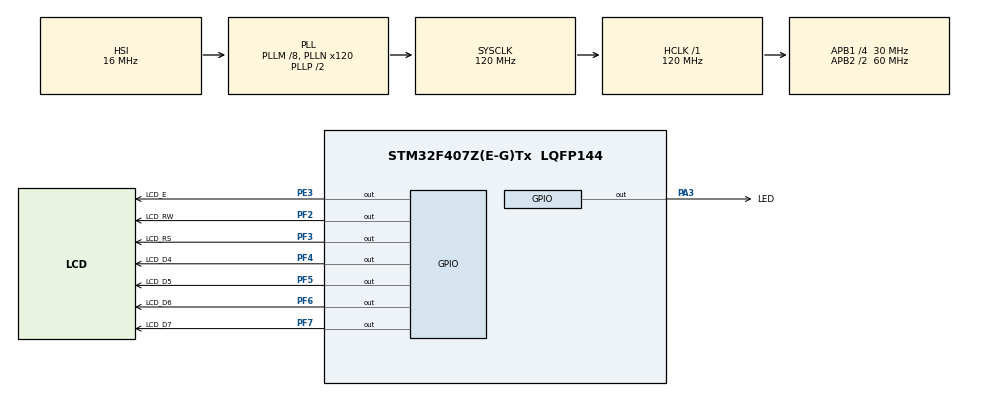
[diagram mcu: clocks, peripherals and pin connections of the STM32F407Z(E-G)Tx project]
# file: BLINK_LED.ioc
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Mcu.Family=STM32F4
Mcu.Name=STM32F407Z(E-G)Tx
Mcu.Package=LQFP144
NVIC.PriorityGroup=NVIC_PRIORITYGROUP_4
PA13.Mode=Serial_Wire
PA13.Signal=SYS_JTMS-SWDIO
PA14.Mode=Serial_Wire
PA14.Signal=SYS_JTCK-SWCLK
PA3.GPIO_Label=LED
PA3.Signal=GPIO_Output
PC14-OSC32_IN.Mode=LSE-External-Oscillator
PC14-OSC32_IN.Signal=RCC_OSC32_IN
PC15-OSC32_OUT.Mode=LSE-External-Oscillator
PC15-OSC32_OUT.Signal=RCC_OSC32_OUT
PE3.GPIO_Label=LCD_E
PE3.Signal=GPIO_Output
PF2.GPIO_Label=LCD_RW
PF2.Signal=GPIO_Output
PF3.GPIO_Label=LCD_RS
PF3.Signal=GPIO_Output
PF4.GPIO_Label=LCD_D4
PF4.Signal=GPIO_Output
PF5.GPIO_Label=LCD_D5
PF5.Signal=GPIO_Output
PF6.GPIO_Label=LCD_D6
PF6.Signal=GPIO_Output
PF7.GPIO_Label=LCD_D7
PF7.Signal=GPIO_Output
PH0-OSC_IN.Mode=HSE-External-Oscillator
PH0-OSC_IN.Signal=RCC_OSC_IN
PH1-OSC_OUT.Mode=HSE-External-Oscillator
PH1-OSC_OUT.Signal=RCC_OSC_OUT
ProjectManager.HeapSize=0x2000
ProjectManager.StackSize=0x4000
ProjectManager.TargetToolchain=MDK-ARM V5
RCC.48MHZClocksFreq_Value=60000000
RCC.AHBFreq_Value=120000000
RCC.APB1CLKDivider=RCC_HCLK_DIV4
RCC.APB1Freq_Value=30000000
RCC.APB1TimFreq_Value=60000000
RCC.APB2CLKDivider=RCC_HCLK_DIV2
RCC.APB2Freq_Value=60000000
RCC.APB2TimFreq_Value=120000000
RCC.CortexFreq_Value=120000000
RCC.HCLKFreq_Value=120000000
RCC.HSE_VALUE=25000000
RCC.HSI_VALUE=16000000
RCC.PLLM=8
RCC.PLLN=120
RCC.SYSCLKFreq_VALUE=120000000
RCC.SYSCLKSource=RCC_SYSCLKSOURCE_PLLCLK
RCC.VCOOutputFreq_Value=240000000
board=custom

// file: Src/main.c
/**
  ******************************************************************************
  * @file           : main.c
  * @brief          : Main program body
  ******************************************************************************
  ** This notice applies to any and all portions of this file
  * that are not between comment pairs USER CODE BEGIN and
  * USER CODE END. Other portions of this file, whether
  * inserted by the user or by software development tools
  * are owned by their respective copyright owners.
  *
  * COPYRIGHT(c) 2023 STMicroelectronics
  *
  * Redistribution and use in source and binary forms, with or without modification,
  * are permitted provided that the following conditions are met:
  *   1. Redistributions of source code must retain the above copyright notice,
  *      this list of conditions and the following disclaimer.
  *   2. Redistributions in binary form must reproduce the above copyright notice,
  *      this list of conditions and the following disclaimer in the documentation
  *      and/or other materials provided with the distribution.
  *   3. Neither the name of STMicroelectronics nor the names of its contributors
  *      may be used to endorse or promote products derived from this software
  *      without specific prior written permission.
  *
  * THIS SOFTWARE IS PROVIDED BY THE COPYRIGHT HOLDERS AND CONTRIBUTORS "AS IS"
  * AND ANY EXPRESS OR IMPLIED WARRANTIES, INCLUDING, BUT NOT LIMITED TO, THE
  * IMPLIED WARRANTIES OF MERCHANTABILITY AND FITNESS FOR A PARTICULAR PURPOSE ARE
  * DISCLAIMED. IN NO EVENT SHALL THE COPYRIGHT HOLDER OR CONTRIBUTORS BE LIABLE
  * FOR ANY DIRECT, INDIRECT, INCIDENTAL, SPECIAL, EXEMPLARY, OR CONSEQUENTIAL
  * DAMAGES (INCLUDING, BUT NOT LIMITED TO, PROCUREMENT OF SUBSTITUTE GOODS OR
  * SERVICES; LOSS OF USE, DATA, OR PROFITS; OR BUSINESS INTERRUPTION) HOWEVER
  * CAUSED AND ON ANY THEORY OF LIABILITY, WHETHER IN CONTRACT, STRICT LIABILITY,
  * OR TORT (INCLUDING NEGLIGENCE OR OTHERWISE) ARISING IN ANY WAY OUT OF THE USE
  * OF THIS SOFTWARE, EVEN IF ADVISED OF THE POSSIBILITY OF SUCH DAMAGE.
  *
  ******************************************************************************
  */
#include "main.h"
#include "stm32f4xx_hal.h"

/* USER CODE BEGIN Includes */
#include "eas_lcd.h"
/* USER CODE END Includes */

/* USER CODE BEGIN PV */
/* Private variables ---------------------------------------------------------*/
uint8_t ucScreen=0;
/* USER CODE END PV */

void SystemClock_Config(void);
static void MX_GPIO_Init(void);

/* USER CODE BEGIN PFP */
/* Private function prototypes -----------------------------------------------*/

/* USER CODE END PFP */

int main(void)
{

  /* MCU Configuration----------------------------------------------------------*/

  /* Reset of all peripherals, Initializes the Flash interface and the Systick. */
  HAL_Init();

  /* Configure the system clock */
  SystemClock_Config();

  /* Initialize all configured peripherals */
  MX_GPIO_Init();
  /* USER CODE BEGIN 2 */
	vLCD_Init();
  /* USER CODE END 2 */

  /* Infinite loop */
  while (1)
  {

  /* USER CODE BEGIN 3 */

		// Show Screen
		if(ucScreen++>=3) ucScreen=0;
		vLCD_Screen(ucScreen);

		// Led Toggle
		HAL_GPIO_TogglePin(LED_GPIO_Port, LED_Pin);
		HAL_Delay(1000);

  }
  /* USER CODE END 3 */

}

void SystemClock_Config(void)
{

  RCC_OscInitTypeDef RCC_OscInitStruct;
  RCC_ClkInitTypeDef RCC_ClkInitStruct;

    /**Configure the main internal regulator output voltage
    */
  __HAL_RCC_PWR_CLK_ENABLE();

  __HAL_PWR_VOLTAGESCALING_CONFIG(PWR_REGULATOR_VOLTAGE_SCALE1);

    /**Initializes the CPU, AHB and APB busses clocks
    */
  RCC_OscInitStruct.OscillatorType = RCC_OSCILLATORTYPE_HSI;
  RCC_OscInitStruct.HSIState = RCC_HSI_ON;
  RCC_OscInitStruct.HSICalibrationValue = 16;
  RCC_OscInitStruct.PLL.PLLState = RCC_PLL_ON;
  RCC_OscInitStruct.PLL.PLLSource = RCC_PLLSOURCE_HSI;
  RCC_OscInitStruct.PLL.PLLM = 8;
  RCC_OscInitStruct.PLL.PLLN = 120;
  RCC_OscInitStruct.PLL.PLLP = RCC_PLLP_DIV2;
  RCC_OscInitStruct.PLL.PLLQ = 4;
  if (HAL_RCC_OscConfig(&RCC_OscInitStruct) != HAL_OK)
  {
    _Error_Handler(__FILE__, __LINE__);
  }

    /**Initializes the CPU, AHB and APB busses clocks
    */
  RCC_ClkInitStruct.ClockType = RCC_CLOCKTYPE_HCLK|RCC_CLOCKTYPE_SYSCLK
                              |RCC_CLOCKTYPE_PCLK1|RCC_CLOCKTYPE_PCLK2;
  RCC_ClkInitStruct.SYSCLKSource = RCC_SYSCLKSOURCE_PLLCLK;
  RCC_ClkInitStruct.AHBCLKDivider = RCC_SYSCLK_DIV1;
  RCC_ClkInitStruct.APB1CLKDivider = RCC_HCLK_DIV4;
  RCC_ClkInitStruct.APB2CLKDivider = RCC_HCLK_DIV2;

  if (HAL_RCC_ClockConfig(&RCC_ClkInitStruct, FLASH_LATENCY_3) != HAL_OK)
  {
    _Error_Handler(__FILE__, __LINE__);
  }

    /**Configure the Systick interrupt time
    */
  HAL_SYSTICK_Config(HAL_RCC_GetHCLKFreq()/1000);

    /**Configure the Systick
    */
  HAL_SYSTICK_CLKSourceConfig(SYSTICK_CLKSOURCE_HCLK);

  /* SysTick_IRQn interrupt configuration */
  HAL_NVIC_SetPriority(SysTick_IRQn, 0, 0);
}

/** Configure pins as
        * Analog
        * Input
        * Output
        * EVENT_OUT
        * EXTI
*/
static void MX_GPIO_Init(void)
{

  GPIO_InitTypeDef GPIO_InitStruct;

  /* GPIO Ports Clock Enable */
  __HAL_RCC_GPIOE_CLK_ENABLE();
  __HAL_RCC_GPIOC_CLK_ENABLE();
  __HAL_RCC_GPIOF_CLK_ENABLE();
  __HAL_RCC_GPIOH_CLK_ENABLE();
  __HAL_RCC_GPIOA_CLK_ENABLE();

  /*Configure GPIO pin Output Level */
  HAL_GPIO_WritePin(LCD_E_GPIO_Port, LCD_E_Pin, GPIO_PIN_RESET);

  /*Configure GPIO pin Output Level */
  HAL_GPIO_WritePin(GPIOF, LCD_RW_Pin|LCD_RS_Pin|LCD_D4_Pin|LCD_D5_Pin
                          |LCD_D6_Pin|LCD_D7_Pin, GPIO_PIN_RESET);

  /*Configure GPIO pin Output Level */
  HAL_GPIO_WritePin(LED_GPIO_Port, LED_Pin, GPIO_PIN_RESET);

  /*Configure GPIO pin : LCD_E_Pin */
  GPIO_InitStruct.Pin = LCD_E_Pin;
  GPIO_InitStruct.Mode = GPIO_MODE_OUTPUT_PP;
  GPIO_InitStruct.Pull = GPIO_NOPULL;
  GPIO_InitStruct.Speed = GPIO_SPEED_FREQ_LOW;
  HAL_GPIO_Init(LCD_E_GPIO_Port, &GPIO_InitStruct);

  /*Configure GPIO pins : LCD_RW_Pin LCD_RS_Pin LCD_D4_Pin LCD_D5_Pin
                           LCD_D6_Pin LCD_D7_Pin */
  GPIO_InitStruct.Pin = LCD_RW_Pin|LCD_RS_Pin|LCD_D4_Pin|LCD_D5_Pin
                          |LCD_D6_Pin|LCD_D7_Pin;
  GPIO_InitStruct.Mode = GPIO_MODE_OUTPUT_PP;
  GPIO_InitStruct.Pull = GPIO_NOPULL;
  GPIO_InitStruct.Speed = GPIO_SPEED_FREQ_LOW;
  HAL_GPIO_Init(GPIOF, &GPIO_InitStruct);

  /*Configure GPIO pin : LED_Pin */
  GPIO_InitStruct.Pin = LED_Pin;
  GPIO_InitStruct.Mode = GPIO_MODE_OUTPUT_PP;
  GPIO_InitStruct.Pull = GPIO_NOPULL;
  GPIO_InitStruct.Speed = GPIO_SPEED_FREQ_LOW;
  HAL_GPIO_Init(LED_GPIO_Port, &GPIO_InitStruct);

}

void _Error_Handler(char *file, int line)
{
  while(1)
  {
  }
}

/************************ (C) COPYRIGHT STMicroelectronics *****END OF FILE****/
